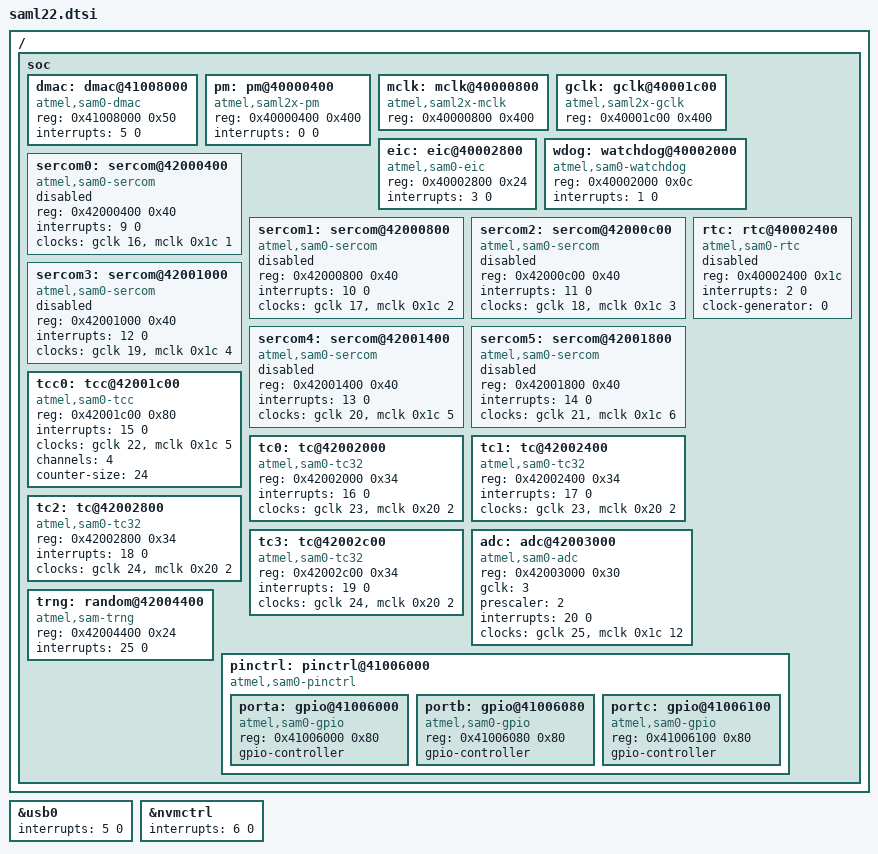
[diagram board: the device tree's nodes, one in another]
/*
 * Copyright (c) 2021 Argentum Systems Ltd.
 *
 * KBH 08/17/2023 most addresses for SAML21 & SAML22 conflict
 * Move most definitions from saml2x.dtsi to part definition file
 *
 * SPDX-License-Identifier: Apache-2.0
 */

#include <atmel/saml2x.dtsi>

/ {
	soc {
		dmac: dmac@41008000 {
			compatible = "atmel,sam0-dmac";
			reg = <0x41008000 0x50>;
			interrupts = <5 0>;
			#dma-cells = <2>;
		};

		pm: pm@40000400 {
			compatible = "atmel,saml2x-pm";
			reg = <0x40000400 0x400>;
			interrupts = <0 0>;
			#clock-cells = <2>;
		};

		mclk: mclk@40000800 {
			compatible = "atmel,saml2x-mclk";
			reg = <0x40000800 0x400>;
			#clock-cells = <2>;
		};

		gclk: gclk@40001c00 {
			compatible = "atmel,saml2x-gclk";
			reg = <0x40001c00 0x400>;
			#clock-cells = <1>;
		};

		eic: eic@40002800 {
			compatible = "atmel,sam0-eic";
			reg = <0x40002800 0x24>;
			interrupts = <3 0>;
		};

		wdog: watchdog@40002000 {
			compatible = "atmel,sam0-watchdog";
			reg = <0x40002000 0x0c>;
			interrupts = <1 0>;
		};

		sercom0: sercom@42000400 {
			compatible = "atmel,sam0-sercom";
			reg = <0x42000400 0x40>;
			status = "disabled";
		};

		sercom1: sercom@42000800 {
			compatible = "atmel,sam0-sercom";
			reg = <0x42000800 0x40>;
			status = "disabled";
		};

		sercom2: sercom@42000c00 {
			compatible = "atmel,sam0-sercom";
			reg = <0x42000c00 0x40>;
			status = "disabled";
		};

		sercom3: sercom@42001000 {
			compatible = "atmel,sam0-sercom";
			reg = <0x42001000 0x40>;
			status = "disabled";
		};

		sercom4: sercom@42001400 {
			compatible = "atmel,sam0-sercom";
			reg = <0x42001400 0x40>;
			status = "disabled";
		};

		sercom5: sercom@42001800 {
			compatible = "atmel,sam0-sercom";
			reg = <0x42001800 0x40>;
			status = "disabled";
		};

		tcc0: tcc@42001c00 {
			compatible = "atmel,sam0-tcc";
			reg = <0x42001c00 0x80>;
			interrupts = <15 0>;
			clocks = <&gclk 22>, <&mclk 0x1c 5>;
			clock-names = "GCLK", "MCLK";

			channels = <4>;
			counter-size = <24>;
		};

        tc0: tc@42002000 {
			compatible = "atmel,sam0-tc32";
			reg = <0x42002000 0x34>;
            interrupts = <16 0>;
            clocks = <&gclk 23>, <&mclk 0x20 2>;
            clock-names = "GCLK", "MCLK";
		};
		
        tc1: tc@42002400 {
			compatible = "atmel,sam0-tc32";
			reg = <0x42002400 0x34>;
            interrupts = <17 0>;
            clocks = <&gclk 23>, <&mclk 0x20 2>;
            clock-names = "GCLK", "MCLK";
		};
		
        tc2: tc@42002800 {
			compatible = "atmel,sam0-tc32";
			reg = <0x42002800 0x34>;
            interrupts = <18 0>;
            clocks = <&gclk 24>, <&mclk 0x20 2>;
            clock-names = "GCLK", "MCLK";
		};
		
        tc3: tc@42002c00 {
			compatible = "atmel,sam0-tc32";
			reg = <0x42002c00 0x34>;
            interrupts = <19 0>;
            clocks = <&gclk 24>, <&mclk 0x20 2>;
            clock-names = "GCLK", "MCLK";
		};
		
        rtc: rtc@40002400 {
			compatible = "atmel,sam0-rtc";
			reg = <0x40002400 0x1c>;
			interrupts = <2 0>;
			clock-generator = <0>;
			status = "disabled";
		};

		adc: adc@42003000 {
			compatible = "atmel,sam0-adc";
			reg = <0x42003000 0x30>;

			/*
			 * 16 MHz max, so clock it with the
			 * 48 MHz DFLL / 2 / 2 = 12 MHz
			 */
			gclk = <3>;
			prescaler = <2>;
			#io-channel-cells = <1>;
		};

		trng: random@42004400 {
			compatible = "atmel,sam-trng";
			reg = <0x42004400 0x24>;
			interrupts = <25 0>;
		};
		
        pinctrl: pinctrl@41006000 {
			compatible = "atmel,sam0-pinctrl";
			#address-cells = <1>;
			#size-cells = <1>;
			ranges = <0x41006000 0x41006000 0x180>;

			porta: gpio@41006000 {
				compatible = "atmel,sam0-gpio";
				reg = <0x41006000 0x80>;
				gpio-controller;
				#gpio-cells = <2>;
				#atmel,pin-cells = <2>;

			};
			portb: gpio@41006080 {
				compatible = "atmel,sam0-gpio";
				reg = <0x41006080 0x80>;
				gpio-controller;
				#gpio-cells = <2>;
				#atmel,pin-cells = <2>;
			};
			portc: gpio@41006100 {
				compatible = "atmel,sam0-gpio";
				reg = <0x41006100 0x80>;
				gpio-controller;
				#gpio-cells = <2>;
				#atmel,pin-cells = <2>;
			};
		};

	};
};

/* declare clocks & interrupts for `saml2x` devices */
&usb0 {
    interrupts = <5 0>;
};

&nvmctrl {
    interrupts = <6 0>;
};

/* declare clocks and interrupts for other devices */
&sercom0 {
	interrupts = <9 0>;
	clocks = <&gclk 16>, <&mclk 0x1c 1>;
	clock-names = "GCLK", "MCLK";
};

&sercom1 {
	interrupts = <10 0>;
	clocks = <&gclk 17>, <&mclk 0x1c 2>;
	clock-names = "GCLK", "MCLK";
};

&sercom2 {
	interrupts = <11 0>;
	clocks = <&gclk 18>, <&mclk 0x1c 3>;
	clock-names = "GCLK", "MCLK";
};

&sercom3 {
	interrupts = <12 0>;
	clocks = <&gclk 19>, <&mclk 0x1c 4>;
	clock-names = "GCLK", "MCLK";
};

&sercom4 {
	interrupts = <13 0>;
	clocks = <&gclk 20>, <&mclk 0x1c 5>;
	clock-names = "GCLK", "MCLK";
};

&sercom5 {
	interrupts = <14 0>;
	clocks = <&gclk 21>, <&mclk 0x1c 6>;
	clock-names = "GCLK", "MCLK";
};

&adc {
	interrupts = <20 0>;
	interrupt-names = "resrdy";
	clocks = <&gclk 25>, <&mclk 0x1c 12>;
	clock-names = "GCLK", "MCLK";
};
